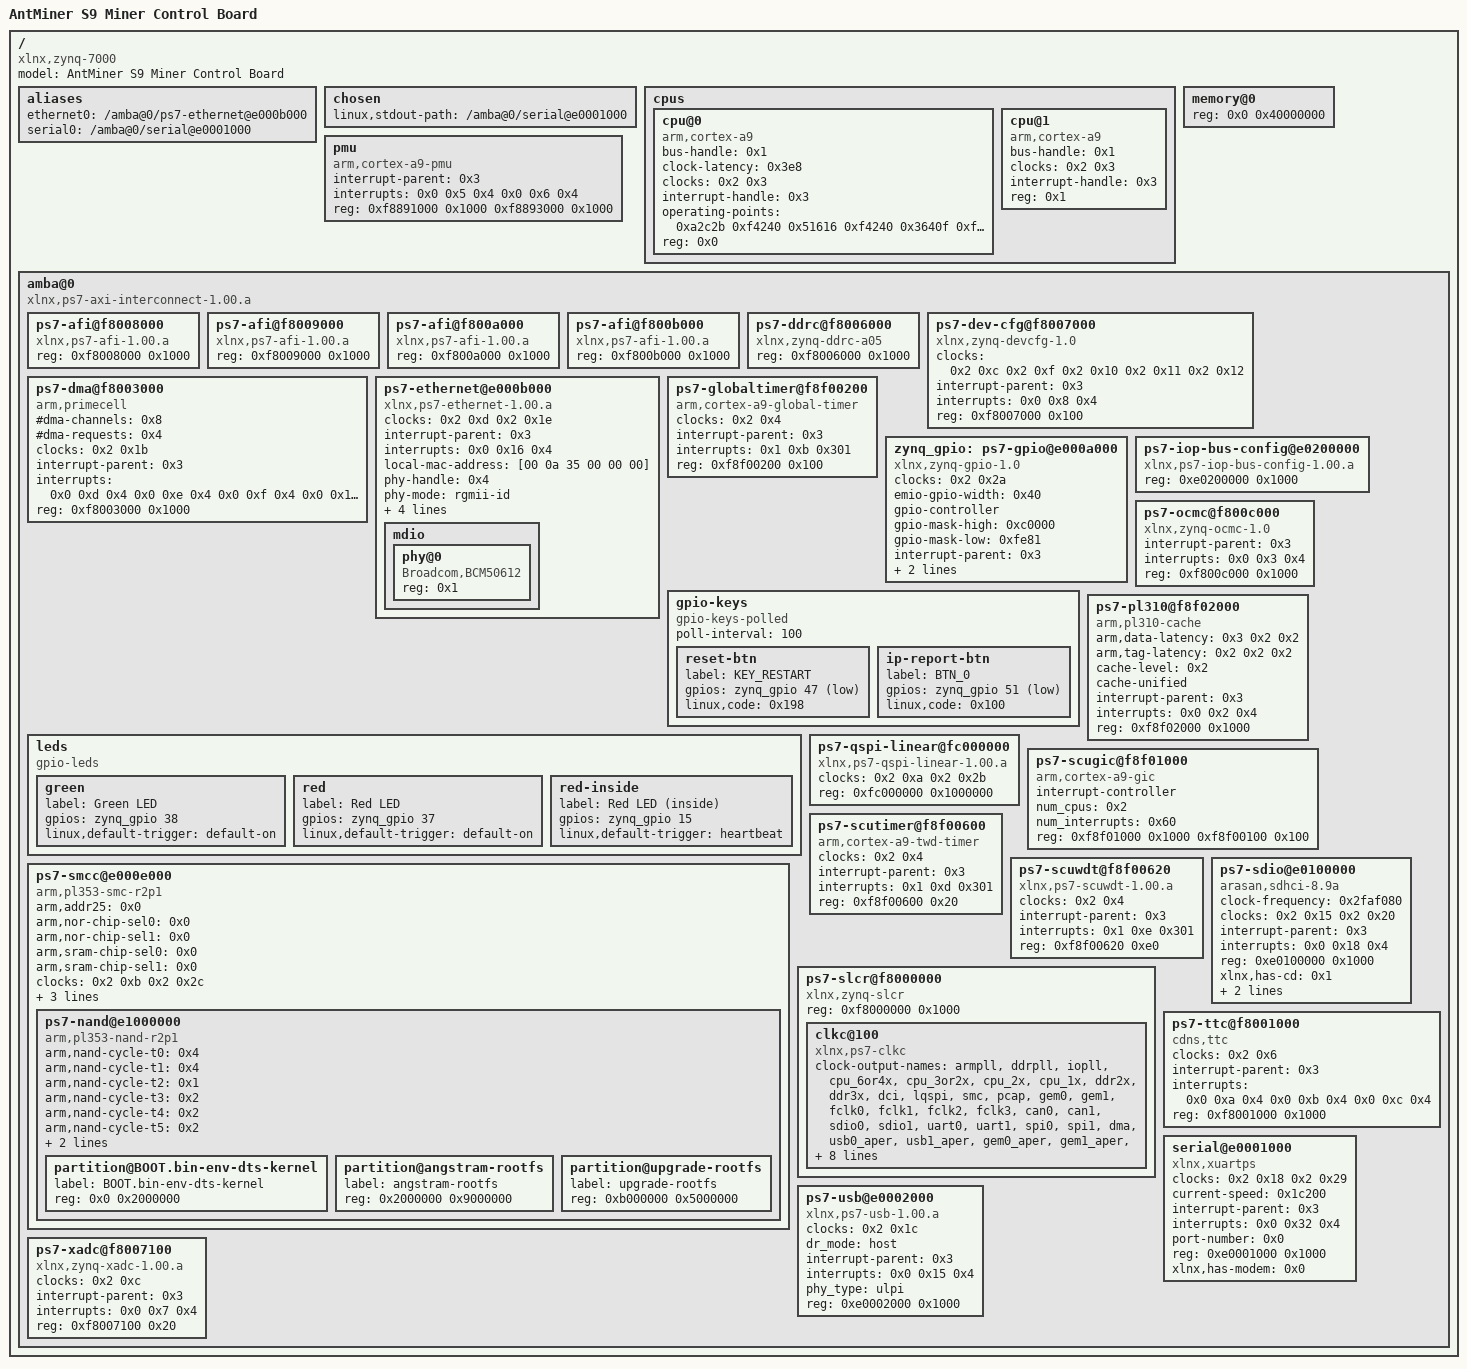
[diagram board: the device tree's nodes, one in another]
/dts-v1/;

/ {
	#address-cells = <0x1>;
	#size-cells = <0x1>;
	model = "AntMiner S9 Miner Control Board";
	compatible = "xlnx,zynq-7000";

	aliases {
		ethernet0 = "/amba@0/ps7-ethernet@e000b000";
		serial0 = "/amba@0/serial@e0001000";
	};

	chosen {
		linux,stdout-path = "/amba@0/serial@e0001000";
	};

	cpus {
		#address-cells = <0x1>;
		#size-cells = <0x0>;

		cpu@0 {
			bus-handle = <0x1>;
			clock-latency = <0x3e8>;
			clocks = <0x2 0x3>;
			compatible = "arm,cortex-a9";
			device_type = "cpu";
			interrupt-handle = <0x3>;
			operating-points = <0xa2c2b 0xf4240 0x51616 0xf4240 0x3640f 0xf4240>;
			reg = <0x0>;
		};

		cpu@1 {
			bus-handle = <0x1>;
			clocks = <0x2 0x3>;
			compatible = "arm,cortex-a9";
			device_type = "cpu";
			interrupt-handle = <0x3>;
			reg = <0x1>;
		};
	};

	pmu {
		compatible = "arm,cortex-a9-pmu";
		interrupt-parent = <0x3>;
		interrupts = <0x0 0x5 0x4 0x0 0x6 0x4>;
		reg = <0xf8891000 0x1000 0xf8893000 0x1000>;
		reg-names = "cpu0", "cpu1";
	};

	memory@0 {
		device_type = "memory";
		reg = <0x0 0x40000000>;
	};

	amba@0 {
		#address-cells = <0x1>;
		#size-cells = <0x1>;
		compatible = "xlnx,ps7-axi-interconnect-1.00.a", "simple-bus";
		ranges;
		linux,phandle = <0x1>;
		phandle = <0x1>;

		ps7-afi@f8008000 {
			compatible = "xlnx,ps7-afi-1.00.a";
			reg = <0xf8008000 0x1000>;
		};

		ps7-afi@f8009000 {
			compatible = "xlnx,ps7-afi-1.00.a";
			reg = <0xf8009000 0x1000>;
		};

		ps7-afi@f800a000 {
			compatible = "xlnx,ps7-afi-1.00.a";
			reg = <0xf800a000 0x1000>;
		};

		ps7-afi@f800b000 {
			compatible = "xlnx,ps7-afi-1.00.a";
			reg = <0xf800b000 0x1000>;
		};

		ps7-ddrc@f8006000 {
			compatible = "xlnx,zynq-ddrc-a05";
			reg = <0xf8006000 0x1000>;
		};

		ps7-dev-cfg@f8007000 {
			clock-names = "ref_clk", "fclk0", "fclk1", "fclk2", "fclk3";
			clocks = <0x2 0xc 0x2 0xf 0x2 0x10 0x2 0x11 0x2 0x12>;
			compatible = "xlnx,zynq-devcfg-1.0";
			interrupt-parent = <0x3>;
			interrupts = <0x0 0x8 0x4>;
			reg = <0xf8007000 0x100>;
		};

		ps7-dma@f8003000 {
			#dma-cells = <0x1>;
			#dma-channels = <0x8>;
			#dma-requests = <0x4>;
			clock-names = "apb_pclk";
			clocks = <0x2 0x1b>;
			compatible = "arm,primecell", "arm,pl330";
			interrupt-names = "abort", "dma0", "dma1", "dma2", "dma3", "dma4", "dma5", "dma6", "dma7";
			interrupt-parent = <0x3>;
			interrupts = <0x0 0xd 0x4 0x0 0xe 0x4 0x0 0xf 0x4 0x0 0x10 0x4 0x0 0x11 0x4 0x0 0x28 0x4 0x0 0x29 0x4 0x0 0x2a 0x4 0x0 0x2b 0x4>;
			reg = <0xf8003000 0x1000>;
		};

		ps7-ethernet@e000b000 {
			#address-cells = <0x1>;
			#size-cells = <0x0>;
			clock-names = "ref_clk", "aper_clk";
			clocks = <0x2 0xd 0x2 0x1e>;
			compatible = "xlnx,ps7-ethernet-1.00.a";
			interrupt-parent = <0x3>;
			interrupts = <0x0 0x16 0x4>;
			local-mac-address = [00 0a 35 00 00 00];
			phy-handle = <0x4>;
			phy-mode = "rgmii-id";
			reg = <0xe000b000 0x1000>;
			xlnx,eth-mode = <0x1>;
			xlnx,has-mdio = <0x1>;
			xlnx,ptp-enet-clock = <0x69f6bcb>;

			mdio {
				#address-cells = <0x1>;
				#size-cells = <0x0>;

				phy@0 {
					compatible = "Broadcom,BCM50612";
					device_type = "ethernet-phy";
					reg = <0x1>;
					linux,phandle = <0x4>;
					phandle = <0x4>;
				};
			};
		};

		ps7-globaltimer@f8f00200 {
			clocks = <0x2 0x4>;
			compatible = "arm,cortex-a9-global-timer";
			interrupt-parent = <0x3>;
			interrupts = <0x1 0xb 0x301>;
			reg = <0xf8f00200 0x100>;
		};

		zynq_gpio: ps7-gpio@e000a000 {
			#gpio-cells = <0x2>;
			clocks = <0x2 0x2a>;
			compatible = "xlnx,zynq-gpio-1.0";
			emio-gpio-width = <0x40>;
			gpio-controller;
			gpio-mask-high = <0xc0000>;
			gpio-mask-low = <0xfe81>;
			interrupt-parent = <0x3>;
			interrupts = <0x0 0x14 0x4>;
			reg = <0xe000a000 0x1000>;
		};

		gpio-keys {
			compatible = "gpio-keys-polled";
			poll-interval = <100>;
			reset-btn {
				label = "KEY_RESTART";
				gpios = <&zynq_gpio 47 1>;
				linux,code = <0x198>;
			};
			ip-report-btn {
				label = "BTN_0";
				gpios = <&zynq_gpio 51 1>;
				linux,code = <0x100>;
			};
		};

		leds {
			compatible = "gpio-leds";
			green {
				label = "Green LED";
				gpios = <&zynq_gpio 38 0>;
				linux,default-trigger = "default-on";
			};
			red {
				label = "Red LED";
				gpios = <&zynq_gpio 37 0>;
				linux,default-trigger = "default-on";
			};
			red-inside {
				label = "Red LED (inside)";
				gpios = <&zynq_gpio 15 0>;
				linux,default-trigger = "heartbeat";
			};
		};

		ps7-iop-bus-config@e0200000 {
			compatible = "xlnx,ps7-iop-bus-config-1.00.a";
			reg = <0xe0200000 0x1000>;
		};

		ps7-ocmc@f800c000 {
			compatible = "xlnx,zynq-ocmc-1.0";
			interrupt-parent = <0x3>;
			interrupts = <0x0 0x3 0x4>;
			reg = <0xf800c000 0x1000>;
		};

		ps7-pl310@f8f02000 {
			arm,data-latency = <0x3 0x2 0x2>;
			arm,tag-latency = <0x2 0x2 0x2>;
			cache-level = <0x2>;
			cache-unified;
			compatible = "arm,pl310-cache";
			interrupt-parent = <0x3>;
			interrupts = <0x0 0x2 0x4>;
			reg = <0xf8f02000 0x1000>;
		};

		ps7-smcc@e000e000 {
			#address-cells = <0x1>;
			#size-cells = <0x1>;
			arm,addr25 = <0x0>;
			arm,nor-chip-sel0 = <0x0>;
			arm,nor-chip-sel1 = <0x0>;
			arm,sram-chip-sel0 = <0x0>;
			arm,sram-chip-sel1 = <0x0>;
			clock-names = "memclk", "aclk";
			clocks = <0x2 0xb 0x2 0x2c>;
			compatible = "arm,pl353-smc-r2p1";
			interrupt-parent = <0x3>;
			interrupts = <0x0 0x12 0x4>;
			ranges;
			reg = <0xe000e000 0x1000>;

			ps7-nand@e1000000 {
				arm,nand-cycle-t0 = <0x4>;
				arm,nand-cycle-t1 = <0x4>;
				arm,nand-cycle-t2 = <0x1>;
				arm,nand-cycle-t3 = <0x2>;
				arm,nand-cycle-t4 = <0x2>;
				arm,nand-cycle-t5 = <0x2>;
				arm,nand-cycle-t6 = <0x4>;
				compatible = "arm,pl353-nand-r2p1";
				reg = <0xe1000000 0x1000000>;
				#address-cells = <0x1>;
				#size-cells = <0x1>;

				partition@BOOT.bin-env-dts-kernel {
					label = "BOOT.bin-env-dts-kernel";
					reg = <0x0 0x2000000>;
				};

				partition@angstram-rootfs {
					label = "angstram-rootfs";
					reg = <0x2000000 0x9000000>;
				};

				partition@upgrade-rootfs {
					label = "upgrade-rootfs";
					reg = <0xb000000 0x5000000>;
				};
			};
		};

		ps7-qspi-linear@fc000000 {
			clock-names = "ref_clk", "aper_clk";
			clocks = <0x2 0xa 0x2 0x2b>;
			compatible = "xlnx,ps7-qspi-linear-1.00.a";
			reg = <0xfc000000 0x1000000>;
		};

		ps7-scugic@f8f01000 {
			#address-cells = <0x2>;
			#interrupt-cells = <0x3>;
			#size-cells = <0x1>;
			compatible = "arm,cortex-a9-gic", "arm,gic";
			interrupt-controller;
			num_cpus = <0x2>;
			num_interrupts = <0x60>;
			reg = <0xf8f01000 0x1000 0xf8f00100 0x100>;
			linux,phandle = <0x3>;
			phandle = <0x3>;
		};

		ps7-scutimer@f8f00600 {
			clocks = <0x2 0x4>;
			compatible = "arm,cortex-a9-twd-timer";
			interrupt-parent = <0x3>;
			interrupts = <0x1 0xd 0x301>;
			reg = <0xf8f00600 0x20>;
		};

		ps7-scuwdt@f8f00620 {
			clocks = <0x2 0x4>;
			compatible = "xlnx,ps7-scuwdt-1.00.a";
			device_type = "watchdog";
			interrupt-parent = <0x3>;
			interrupts = <0x1 0xe 0x301>;
			reg = <0xf8f00620 0xe0>;
		};

		ps7-sdio@e0100000 {
			clock-frequency = <0x2faf080>;
			clock-names = "clk_xin", "clk_ahb";
			clocks = <0x2 0x15 0x2 0x20>;
			compatible = "arasan,sdhci-8.9a";
			interrupt-parent = <0x3>;
			interrupts = <0x0 0x18 0x4>;
			reg = <0xe0100000 0x1000>;
			xlnx,has-cd = <0x1>;
			xlnx,has-power = <0x0>;
			xlnx,has-wp = <0x0>;
		};

		ps7-slcr@f8000000 {
			#address-cells = <0x1>;
			#size-cells = <0x1>;
			compatible = "xlnx,zynq-slcr", "syscon";
			ranges;
			reg = <0xf8000000 0x1000>;

			clkc@100 {
				#clock-cells = <0x1>;
				clock-output-names = "armpll", "ddrpll", "iopll", "cpu_6or4x", "cpu_3or2x", "cpu_2x", "cpu_1x", "ddr2x", "ddr3x", "dci", "lqspi", "smc", "pcap", "gem0", "gem1", "fclk0", "fclk1", "fclk2", "fclk3", "can0", "can1", "sdio0", "sdio1", "uart0", "uart1", "spi0", "spi1", "dma", "usb0_aper", "usb1_aper", "gem0_aper", "gem1_aper", "sdio0_aper", "sdio1_aper", "spi0_aper", "spi1_aper", "can0_aper", "can1_aper", "i2c0_aper", "i2c1_aper", "uart0_aper", "uart1_aper", "gpio_aper", "lqspi_aper", "smc_aper", "swdt", "dbg_trc", "dbg_apb";
				compatible = "xlnx,ps7-clkc";
				fclk-enable = <0xf>;
				ps-clk-frequency = <0x1fca055>;
				reg = <0x100 0x100>;
				linux,phandle = <0x2>;
				phandle = <0x2>;
			};
		};

		ps7-ttc@f8001000 {
			clocks = <0x2 0x6>;
			compatible = "cdns,ttc";
			interrupt-names = "ttc0", "ttc1", "ttc2";
			interrupt-parent = <0x3>;
			interrupts = <0x0 0xa 0x4 0x0 0xb 0x4 0x0 0xc 0x4>;
			reg = <0xf8001000 0x1000>;
		};

		serial@e0001000 {
			clock-names = "uart_clk", "pclk";
			clocks = <0x2 0x18 0x2 0x29>;
			compatible = "xlnx,xuartps", "cdns,uart-r1p8";
			current-speed = <0x1c200>;
			device_type = "serial";
			interrupt-parent = <0x3>;
			interrupts = <0x0 0x32 0x4>;
			port-number = <0x0>;
			reg = <0xe0001000 0x1000>;
			xlnx,has-modem = <0x0>;
		};

		ps7-usb@e0002000 {
			clocks = <0x2 0x1c>;
			compatible = "xlnx,ps7-usb-1.00.a", "xlnx,zynq-usb-1.00.a";
			dr_mode = "host";
			interrupt-parent = <0x3>;
			interrupts = <0x0 0x15 0x4>;
			phy_type = "ulpi";
			reg = <0xe0002000 0x1000>;
		};

		ps7-xadc@f8007100 {
			clocks = <0x2 0xc>;
			compatible = "xlnx,zynq-xadc-1.00.a";
			interrupt-parent = <0x3>;
			interrupts = <0x0 0x7 0x4>;
			reg = <0xf8007100 0x20>;
		};
	};
};
